# STM32G491 register map
File version: 1.9
CPU: CM4 r0p1, little endian, MPU, FPU, 4 interrupt priority bits
Registers are 32-bit, read-write, reset 0x0 unless marked. A register's access mark holds for its fields unless they carry their own. Offsets are from the block's base; [hi:lo] are bit positions; {n}, {i} and the like mark numbered series; 'fields as' and 'values as' point back to an identical list.

## VREFBUF — Voltage reference buffer
Base 0x40010030
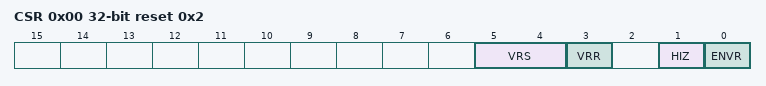
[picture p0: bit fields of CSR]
0x00 CSR access per field reset 0x2 — VREF_BUF Control and Status Register
  [5:4] VRS rw — Voltage reference scale
  [3] VRR ro — Voltage reference buffer ready
  [1] HIZ rw — High impedence mode for the VREF_BUF
  [0] ENVR rw — Enable Voltage Reference
0x04 CCR — VREF_BUF Calibration Control Register
  [5:0] TRIM — Trimming code

## COMP — Comparator control and status register
Base 0x40010200
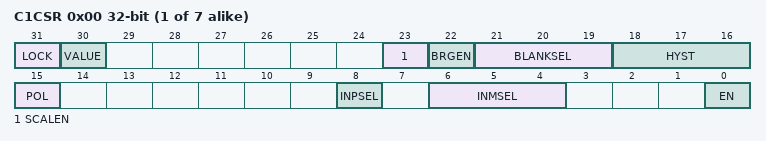
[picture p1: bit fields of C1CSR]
0x00 C{i}CSR (i=1..7; step 0x4) access per field — Comparator control/status register
  [31] LOCK rw, [30] VALUE ro, [23] SCALEN rw, [22] BRGEN rw, [21:19] BLANKSEL rw, [18:16] HYST rw, [15] POL rw, [8] INPSEL rw, [6:4] INMSEL rw, [0] EN rw

## ADC12_Common — Analog-to-Digital Converter
Base 0x50000300
Same registers: ADC345_Common 0x50000700
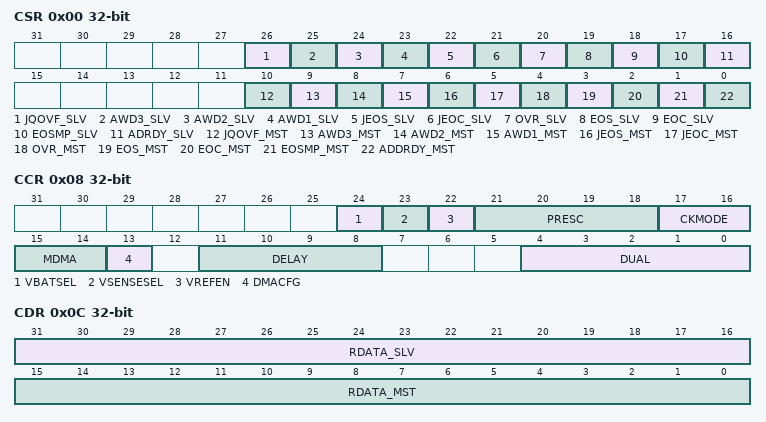
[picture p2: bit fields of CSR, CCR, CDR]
0x00 CSR ro — ADC Common status register
  [26] JQOVF_SLV — Injected Context Queue Overflow flag of the slave ADC
    0=NoOverflow (No injected context queue overflow has occurred); 1=Overflow (Injected context queue overflow has occurred)
  [25] AWD3_SLV — Analog watchdog 3 flag of the slave ADC
    0=NoEvent (No analog watchdog event occurred); 1=Event (Analog watchdog event occurred)
  [24] AWD2_SLV — Analog watchdog 2 flag of the slave ADC
    values as AWD3_SLV
  [23] AWD1_SLV — Analog watchdog 1 flag of the slave ADC
    values as AWD3_SLV
  [22] JEOS_SLV — End of injected sequence flag of the slave ADC
    0=NotComplete (Injected sequence is not complete); 1=Complete (Injected sequence complete)
  [21] JEOC_SLV — End of injected conversion flag of the slave ADC
    0=NotComplete (Injected conversion is not complete); 1=Complete (Injected conversion complete)
  [20] OVR_SLV — Overrun flag of the slave ADC
    0=No overrun occurred; 1=Overrun occurred
  [19] EOS_SLV — End of regular sequence flag of the slave ADC
    0=NotComplete (Regular sequence is not complete); 1=Complete (Regular sequence complete)
  [18] EOC_SLV — End of regular conversion of the slave ADC
    0=NotComplete (Regular conversion is not complete); 1=Complete (Regular conversion complete)
  [17] EOSMP_SLV
    0=NotEnded (End of sampling phase no yet reached); 1=Ended (End of sampling phase reached)
  [16] ADRDY_SLV
    0=NotReady (ADC is not ready to start conversion); 1=Ready (ADC is ready to start conversion)
  [10] JQOVF_MST
    values as JQOVF_SLV
  [9] AWD3_MST
    values as AWD3_SLV
  [8] AWD2_MST
    values as AWD3_SLV
  [7] AWD1_MST
    values as AWD3_SLV
  [6] JEOS_MST
    values as JEOS_SLV
  [5] JEOC_MST
    values as JEOC_SLV
  [4] OVR_MST
    0=No overrun occurred; 1=Overrun occurred
  [3] EOS_MST
    values as EOS_SLV
  [2] EOC_MST
    values as EOC_SLV
  [1] EOSMP_MST
    values as EOSMP_SLV
  [0] ADDRDY_MST
0x08 CCR — ADC common control register
  [24] VBATSEL — VBAT selection
    0=Disabled (V_BAT channel disabled); 1=Enabled (V_BAT channel enabled)
  [23] VSENSESEL — VTS selection
    0=Disabled (Temperature sensor channel disabled); 1=Enabled (Temperature sensor channel enabled)
  [22] VREFEN — VREFINT enable
    0=Disabled (V_REFINT channel disabled); 1=Enabled (V_REFINT channel enabled)
  [21:18] PRESC — ADC prescaler
  [17:16] CKMODE — ADC clock mode
    0=Asynchronous (Use Kernel Clock adc_ker_ck_input divided by PRESC. Asynchronous to AHB clock); 1=SyncDiv1 (Use AHB clock rcc_hclk3. In this case rcc_hclk must equal sys_d1cpre_ck); 2=SyncDiv2 (Use AHB clock rcc_hclk3 divided by 2); 3=SyncDiv4 (Use AHB clock rcc_hclk3 divided by 4)
  [15:14] MDMA — Direct memory access mode for multi ADC mode
  [13] DMACFG — DMA configuration (for multi-ADC mode)
  [11:8] DELAY — Delay between 2 sampling phases
  [4:0] DUAL — Dual ADC mode selection
    0=Independent mode; 1=DualRJ (Dual, combined regular simultaneous + injected simultaneous mode); 2=DualRA (Dual, combined regular simultaneous + alternate trigger mode); 3=DualIJ (Dual, combined interleaved mode + injected simultaneous mode); 5=DualJ (Dual, injected simultaneous mode only); 6=Dual, regular simultaneous mode only; 7=Dual, interleaved mode only; 9=Dual, alternate trigger mode only
0x0C CDR ro — ADC common regular data register for dual and triple modes
  [31:16] RDATA_SLV — Regular data of the slave ADC
  [15:0] RDATA_MST — Regular data of the master ADC
